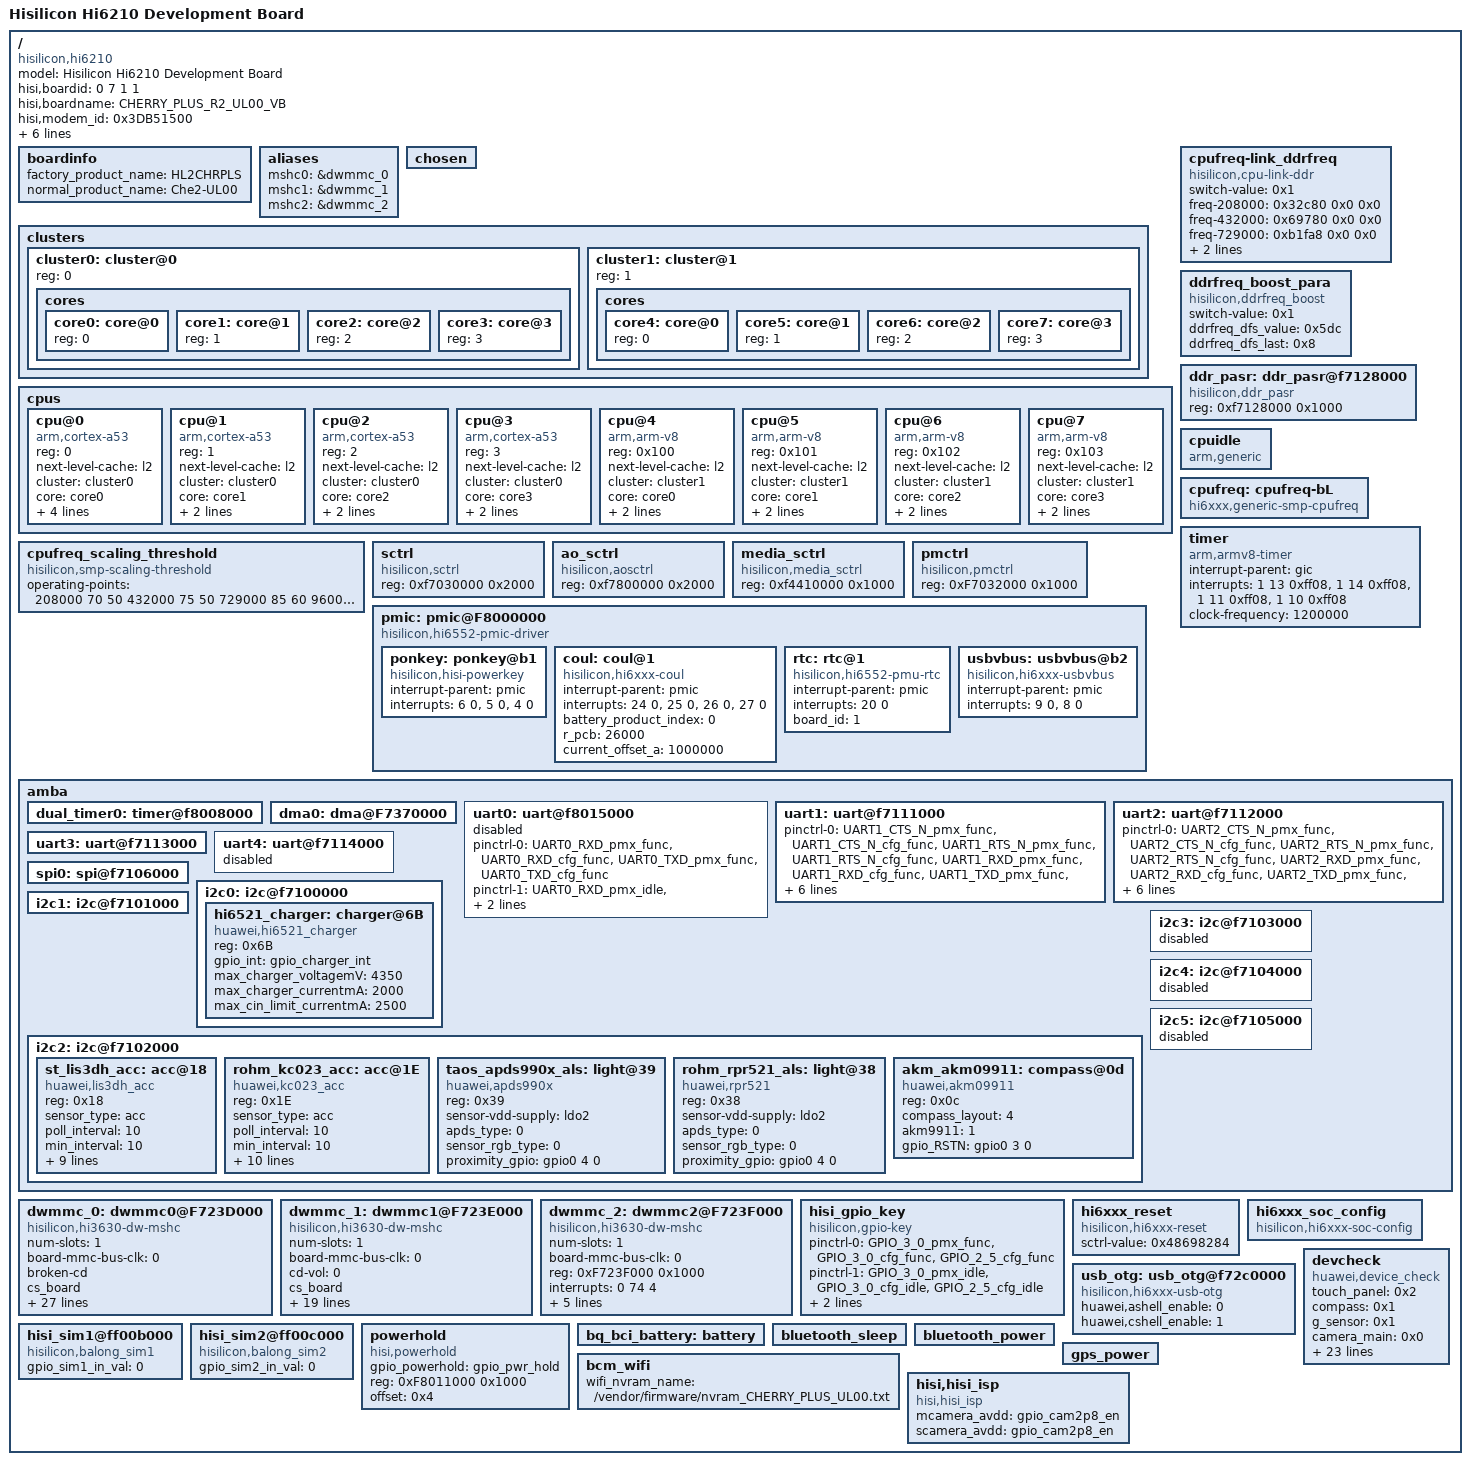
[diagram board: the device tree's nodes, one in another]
/*
 *  Copyright (C) 2014 Hisilicon Ltd.
 *  Author: Bintian Wang <bintian.wang@huawei.com>
 *
 *  This program is free software; you can redistribute it and/or modify
 *  it under the terms of the GNU General Public License version 2 as
 *  publishhed by the Free Software Foundation.
 */

/dts-v1/;
/memreserve/ 0x07000000 0x00400000;
/include/ "skeleton.dtsi"
/include/ "CHERRY_PLUS_R2_UL00_VB_pin.dtsi"
/include/ "./cherry_plus_r2/hi6220_gpio.dtsi"
/include/ "./cherry_plus_r2/hi6220_pinctrl.dtsi"
/include/ "CHERRY_PLUS_R2_UL00_VB_charger.dtsi"
/include/ "CHERRY_PLUS_R2_UL00_VB_pmic.dtsi"
/include/ "CHERRY_PLUS_R2_UL00_VB_gpio_logic.dtsi"
/include/ "./cherry_plus_r2/hi6220.dtsi"
/include/ "./cherry_plus_r2/hi6220_clk.dtsi"
/include/ "./cherry_plus_r2/hi6552_pmuclk.dtsi"
/include/ "./cherry_plus_r2/hi6xxx_ddr3.dtsi"
/include/ "./cherry_plus_r2/hi6552_pmic_mntn.dtsi"
/include/ "./cherry_plus_r2/hi6xxx_mtcmos.dtsi"
/include/ "./cherry_plus_r2/hi6220_memory.dtsi"
/include/ "./cherry_plus_r2/bq_bci_battery.dtsi"
/include/ "./cherry_plus_r2/hi6220_touchscreen.dtsi"
/include/ "./cherry_plus_r2/hi6220_vcodec.dtsi"
/include/ "./cherry_plus_r2/hi6220_camera.dtsi"
/include/ "./cherry_plus_r2/hi6220_videoconfig.dtsi"
/include/ "./cherry_plus_r2/hi6220_mali450.dtsi"
/include/ "./cherry_plus_r2/hi6220_fb.dtsi"
/include/ "./cherry_plus_r2/hi6220_mipi_tm_nt35521.dtsi"
/include/ "./cherry_plus_r2/hi6220_mipi_boe_nt35521.dtsi" 
/include/ "./cherry_plus_r2/hi6220_mipi_cmi_nt35521.dtsi" 
/include/ "./cherry_plus_r2/hi6220_mipi_yassy_hx8394.dtsi"
/include/ "./cherry_plus_r2/hi6220_mipi_tm_r61318.dtsi"
/include/ "./cherry_plus_r2/hi6220_mipi_cmi_otm1284a.dtsi"
/include/ "./cherry_plus_r2/hi6220_mipi_yassy_ili9881-3.dtsi"

/* /include/ "./cherry_plus_r2/hi6220_otm1282b.dtsi" */
/include/ "./cherry_plus_r2/hi6220_mipi_jdi_otm1902b.dtsi"
/include/ "./cherry_plus_r2/test_hi6xxx_regulator.dtsi"
/include/ "./cherry_plus_r2/hi6220_tsensor.dtsi"
/include/ "./cherry_plus_r2/hi6xxx_hkadc.dtsi"
/include/ "./cherry_plus_r2/hi6220_audio.dtsi"
/include/ "./cherry_plus_r2/hi6220_clk_stub.dtsi"
/include/ "./cherry_plus_r2/hi6220_hall.dtsi"

/include/ "./cherry_plus_r2/hisi_vibrator.dtsi"
/include/ "./cherry_plus_r2/huawei_wifi.dtsi"
/include/ "./cherry_plus_r2/huawei_bluetooth.dtsi"
/include/ "./cherry_plus_r2/huawei_gps.dtsi"
/include/ "./cherry_plus_r2/hisi_hi6xxx_noc.dtsi"
/include/ "./cherry_plus_r2/huawei_connectivity.dtsi"
/ {
	model = "Hisilicon Hi6210 Development Board";
	compatible = "hisilicon,hi6210";
	hisi,boardid = <0 7 1 1>;
	hisi,boardname = "CHERRY_PLUS_R2_UL00_VB";
	hisi,modem_id = <0x3DB51500>;
	hisi,product_name = "CHERRY_PLUS_UL00";
	mntn,acpu-scaddr = <0xf6504000 0x1000>;
	power,busdfs = <0x1>;
	power,localtimer = <0x0>;
	clk,support_odd_div = <0>;
	#address-cells = <1>;
	#size-cells = <1>;
	interrupt-parent = <&gic>;
	
	boardinfo{
	factory_product_name = "HL2CHRPLS";
	normal_product_name = "Che2-UL00";
	};
	aliases{
	    mshc0 = &dwmmc_0;
	    mshc1 = &dwmmc_1;
	    mshc2 = &dwmmc_2;
	};

	chosen {};

	clusters {
		#address-cells = <1>;
		#size-cells = <0>;

		cluster0: cluster@0 { /*A53 cluster*/
			reg = <0>;
			cores {
				#address-cells = <1>;
				#size-cells = <0>;

				core0: core@0 {
					reg = <0>;
				};

				core1: core@1 {
					reg = <1>;
				};

				core2: core@2 {
					reg = <2>;
				};

				core3: core@3 {
					reg = <3>;
				};

			};
		};

		cluster1: cluster@1 { /*A53 cluster*/
			reg = <1>;
			cores {
				#address-cells = <1>;
				#size-cells = <0>;

				core4: core@0 {
					reg = <0>;
				};

				core5: core@1 {
					reg = <1>;
				};

				core6: core@2 {
					reg = <2>;
				};

				core7: core@3 {
					reg = <3>;
				};
			};
		};
	};

	cpus {
		#address-cells = <1>;
		#size-cells = <0>;

		cpu@0 {
			compatible = "arm,cortex-a53";
			device_type = "cpu";
			reg = <0>;
			next-level-cache = <&l2>;			
			cluster = <&cluster0>;
			core = <&core0>;
			clock-frequency = <0>;
			clock-latency = <0>;
			operating-points = <
				/* kHz  uV */
				208000  0
				432000  0
				729000  0
				960000  0
				1200000 0
			>;
			
		};

		cpu@1 {
			compatible = "arm,cortex-a53";
			device_type = "cpu";
			reg = <1>;
			next-level-cache = <&l2>;
			cluster = <&cluster0>;
			core = <&core1>;
			clock-frequency = <0>;
			clock-latency = <0>;
		};

		cpu@2 {
			compatible = "arm,cortex-a53";
			device_type = "cpu";
			reg = <2>;
			next-level-cache = <&l2>;
			cluster = <&cluster0>;
			core = <&core2>;
			clock-frequency = <0>;
			clock-latency = <0>;
		};

		cpu@3 {
			compatible = "arm,cortex-a53";
			device_type = "cpu";
			reg = <3>;
			next-level-cache = <&l2>;
			cluster = <&cluster0>;
			core = <&core3>;
			clock-frequency = <0>;
			clock-latency = <0>;
		};
		cpu@4 {
			compatible = "arm,arm-v8";
			device_type = "cpu";
			reg = <0x100>;
			next-level-cache = <&l2>;
			cluster = <&cluster1>;
			core = <&core0>;
			clock-frequency = <0>;
			clock-latency = <0>;
		};
		cpu@5 {
			compatible = "arm,arm-v8";
			device_type = "cpu";
			reg = <0x101>;
			next-level-cache = <&l2>;
			cluster = <&cluster1>;
			core = <&core1>;
			clock-frequency = <0>;
			clock-latency = <0>;
		};
		cpu@6 {
			compatible = "arm,arm-v8";
			device_type = "cpu";
			reg = <0x102>;
			next-level-cache = <&l2>;
			cluster = <&cluster1>;
			core = <&core2>;
			clock-frequency = <0>;
			clock-latency = <0>;
		};
		cpu@7 {
			compatible = "arm,arm-v8";
			device_type = "cpu";
			reg = <0x103>;
			next-level-cache = <&l2>;
			cluster = <&cluster1>;
			core = <&core3>;
			clock-frequency = <0>;
			clock-latency = <0>;
		};
		
	};	
	cpufreq-link_ddrfreq {
	        compatible = "hisilicon,cpu-link-ddr";
			switch-value = <0x1>;
			freq-208000 = <0x32c80 0x0 0x0>;
			freq-432000 = <0x69780 0x0 0x0>;
			freq-729000 = <0xb1fa8 0x0 0x0>;
			freq-960000 = <0xea600 0x0 0x61a80>;
			freq-1200000 = <0x124f80 0x0 0x61a80>;
        };

    ddrfreq_boost_para {
            compatible = "hisilicon,ddrfreq_boost";
            switch-value = <0x1>; 
            ddrfreq_dfs_value = <0x5dc>;   
            ddrfreq_dfs_last = <0x8>; 
        };  
    /* ddr pasr */
    ddr_pasr: ddr_pasr@f7128000 {
        compatible = "hisilicon,ddr_pasr";
        reg = <0xf7128000 0x1000>;
        status = "ok";
    };  
	cpuidle {
	        compatible = "arm,generic";
	        status = "ok";
        };
	
	/* cpufreq  device */
	cpufreq: cpufreq-bL {
		compatible = "hi6xxx,generic-smp-cpufreq";
	};

        cpufreq_scaling_threshold {
                compatible = "hisilicon,smp-scaling-threshold";
                operating-points = <
                        /* kHz  up_threshold down_threshold*/
                        208000   70   50
                        432000   75   50
                        729000   85   60
                        960000   85   70
                        1200000  90   70
                >;
        };

	timer {
	    compatible = "arm,armv8-timer";
	    interrupt-parent = <&gic>;
	    interrupts = <1 13 0xff08>,
	                 <1 14 0xff08>,
	                 <1 11 0xff08>,
	                 <1 10 0xff08>;
	    clock-frequency = <1200000>;
	};

	sctrl: sctrl {
		compatible = "hisilicon,sctrl";
		reg = <0xf7030000 0x2000>;
		status = "ok";
	};

	ao_sctrl: ao_sctrl {
		compatible = "hisilicon,aosctrl";
		reg = <0xf7800000 0x2000>;
		status = "ok";
	};
	
	media_sctrl: media_sctrl {
		compatible = "hisilicon,media_sctrl";
		reg = <0xf4410000 0x1000>;
		status = "ok";
	};

	pmctrl: pmctrl {
		compatible = "hisilicon,pmctrl";
		reg = <0xF7032000 0x1000>;
		status = "ok";
	};
        pmic: pmic@F8000000 {
                compatible = "hisilicon,hi6552-pmic-driver";
                status = "ok";
                ponkey:ponkey@b1{
                        compatible = "hisilicon,hisi-powerkey";
                        interrupt-parent = <&pmic>;
                        interrupts = <6 0>, <5 0>, <4 0>;
                        interrupt-names = "down", "up", "hold 1s";
                };
                coul: coul@1 {
                        compatible = "hisilicon,hi6xxx-coul";
                        interrupt-parent = <&pmic>;
                        interrupts = <24 0>, <25 0>, <26 0>, <27 0>;
                        interrupt-names = "cl_int_i", "cl_out_i", "cl_in_i", "vbat_int_i";
						battery_product_index = <0>;
						r_pcb = <26000>;	
						current_offset_a = <1000000>;						
						status = "ok";
                };
			
                rtc: rtc@1 {
                        compatible = "hisilicon,hi6552-pmu-rtc";
                        interrupt-parent = <&pmic>;
                        interrupts = <20 0>;
                        interrupt-names = "hi6552_pmu_rtc";
						board_id = <1>;
                };
                usbvbus:usbvbus@b2{
			compatible = "hisilicon,hi6xxx-usbvbus";
			interrupt-parent = <&pmic>;
			interrupts = <9 0>, <8 0>;
			interrupt-names = "connect", "disconnect";
		};
	};

	amba {
		dual_timer0: timer@f8008000 {
			status = "ok";
		};

		dma0: dma@F7370000 {
			status = "ok";
		};

		uart0: uart@f8015000 {	/* console */
			pinctrl-names = "default", "idle";
			pinctrl-0 = <&UART0_RXD_pmx_func
			             &UART0_RXD_cfg_func
				     &UART0_TXD_pmx_func
				     &UART0_TXD_cfg_func>;
			pinctrl-1 = <&UART0_RXD_pmx_idle
			             &UART0_RXD_cfg_idle
				     &UART0_TXD_pmx_idle
			             &UART0_TXD_cfg_idle>;
			status = "disabled";
		};
		uart1: uart@f7111000 {
			pinctrl-names = "default", "idle";
			pinctrl-0 = <&UART1_CTS_N_pmx_func
			             &UART1_CTS_N_cfg_func
			             &UART1_RTS_N_pmx_func
				     &UART1_RTS_N_cfg_func
				     &UART1_RXD_pmx_func
				     &UART1_RXD_cfg_func
				     &UART1_TXD_pmx_func
				     &UART1_TXD_cfg_func>;
			pinctrl-1 = <&UART1_CTS_N_pmx_idle
			             &UART1_CTS_N_cfg_idle
			             &UART1_RTS_N_pmx_idle
				     &UART1_RTS_N_cfg_idle
				     &UART1_RXD_pmx_idle
				     &UART1_RXD_cfg_idle
				     &UART1_TXD_pmx_idle
				     &UART1_TXD_cfg_idle>;
			status = "ok";
		};
		uart2: uart@f7112000 {
			pinctrl-names = "default", "idle";
			pinctrl-0 = <&UART2_CTS_N_pmx_func
			             &UART2_CTS_N_cfg_func
			             &UART2_RTS_N_pmx_func
				     &UART2_RTS_N_cfg_func
				     &UART2_RXD_pmx_func
				     &UART2_RXD_cfg_func
				     &UART2_TXD_pmx_func
				     &UART2_TXD_cfg_func>;
			pinctrl-1 = <&UART2_CTS_N_pmx_idle
			             &UART2_CTS_N_cfg_idle
			             &UART2_RTS_N_pmx_idle
				     &UART2_RTS_N_cfg_idle
				     &UART2_RXD_pmx_idle
				     &UART2_RXD_cfg_idle
				     &UART2_TXD_pmx_idle
				     &UART2_TXD_cfg_idle>;
			status = "ok";
		};
		uart3: uart@f7113000 {
			status = "ok";
		};
		uart4: uart@f7114000 {
			status = "disabled";
		};

		spi0: spi@f7106000 {	
			status = "ok";
		};

		/*i2c bus node*/
		i2c0: i2c@f7100000 {
			status = "ok";
			hi6521_charger:charger@6B {
				compatible = "huawei,hi6521_charger";
				reg = <0x6B>;				
				gpio_int = <&gpio_charger_int>;
				max_charger_voltagemV = <4350>;
				max_charger_currentmA = <2000>;
				max_cin_limit_currentmA = <2500>;
				status = "ok";
			};

		};
		i2c1: i2c@f7101000 {
			status = "ok";			
		};
		i2c2: i2c@f7102000 {
			status = "ok";
			st_lis3dh_acc:acc@18{
				compatible="huawei,lis3dh_acc";
				reg = <0x18>;
				sensor_type="acc";
				poll_interval=<10>;
				min_interval=<10>;
				g_range=<0>;
				axis_map_x=<0>;
				axis_map_y=<1>;
				axis_map_z=<2>;
				negate_x=<1>;
				negate_y=<1>;
				negate_z=<0>;
				gpio_int1=<0>;
				gpio_int2=<0>;
				status = "ok";
			};
			rohm_kc023_acc:acc@1E{
				compatible="huawei,kc023_acc";
				reg = <0x1E>;
				sensor_type="acc";
				poll_interval=<10>;
				min_interval=<10>;
				g_range=<0>;
				accel_res=<3>;
				axis_map_x=<0>;
				axis_map_y=<1>;
				axis_map_z=<2>;
				negate_x=<1>;
				negate_y=<1>;
				negate_z=<0>;
				gpio_int1=<0>;
				gpio_int2=<0>;
				status = "ok";
			};
			taos_apds990x_als:light@39{
				compatible="huawei,apds990x";
				reg = <0x39>;
				sensor-vdd-supply = <&ldo2>;
				apds_type=<0>;
				sensor_rgb_type=<0>;
				proximity_gpio=<&gpio0 4 0>;
				status = "ok";
			};
			rohm_rpr521_als:light@38{
				compatible="huawei,rpr521";
				reg = <0x38>;
				sensor-vdd-supply = <&ldo2>;
				apds_type=<0>;
				sensor_rgb_type=<0>;
				proximity_gpio=<&gpio0 4 0>;
				status = "ok";
			};
			akm_akm09911:compass@0d{
				compatible="huawei,akm09911";
				reg = <0x0c>;
				compass_layout=<4>;
				akm9911=<1>;
				gpio_RSTN=<&gpio0 3 0>;
				status = "ok";
			};
		};
		i2c3: i2c@f7103000 {
			status = "disabled";
		};
		i2c4: i2c@f7104000 {
			status = "disabled";
		};
		i2c5: i2c@f7105000 {
			status = "disabled";
		};

	};
	
	/*watchpoint: watchpoint@F6580000 {
		compatible = "hisilicon,watchpoint";
		status = "ok";
	};*/
	/* emmc */
	dwmmc_0: dwmmc0@F723D000 {
 		compatible = "hisilicon,hi3630-dw-mshc";
		num-slots = <1>;
		board-mmc-bus-clk = <0>;
		broken-cd;
		cs_board;
        	caps2-mmc-hs200-1_8v;
 	        reg = <0xF723D000 0x1000>;
 		interrupts = <0 72 4>;
 		#address-cells = <1>;
 		#size-cells = <0>;
 		clocks = <&clk_mmc0_sample>, <&clk_mmc0>;
 		clock-names = "ciu", "biu";
		vmmc-supply = <&ldo19>;
		pinctrl-names = "default","idle";
		pinctrl-0 = <&EMMC_CLK_pmx_func
			         &EMMC_CLK_cfg_func
					 &EMMC_CMD_pmx_func
			         &EMMC_CMD_cfg_func
					 &EMMC_DATA0_pmx_func
					 &EMMC_DATA0_cfg_func
					 &EMMC_DATA1_pmx_func
					 &EMMC_DATA1_cfg_func
					 &EMMC_DATA2_pmx_func
					 &EMMC_DATA2_cfg_func
					 &EMMC_DATA3_pmx_func
					 &EMMC_DATA3_cfg_func
					 &EMMC_DATA4_pmx_func
					 &EMMC_DATA4_cfg_func
					 &EMMC_DATA5_pmx_func
					 &EMMC_DATA5_cfg_func
					 &EMMC_DATA6_pmx_func
					 &EMMC_DATA6_cfg_func
					 &EMMC_DATA7_pmx_func
					 &EMMC_DATA7_cfg_func>;
		pinctrl-1 = <&EMMC_CLK_pmx_idle
			         &EMMC_CLK_cfg_idle
					 &EMMC_CMD_pmx_idle
					 &EMMC_CMD_cfg_idle
					 &EMMC_DATA0_pmx_idle
					 &EMMC_DATA0_cfg_idle
					 &EMMC_DATA1_pmx_idle
					 &EMMC_DATA1_cfg_idle
					 &EMMC_DATA2_pmx_idle
					 &EMMC_DATA2_cfg_idle
					 &EMMC_DATA3_pmx_idle
					 &EMMC_DATA3_cfg_idle
					 &EMMC_DATA4_pmx_idle
					 &EMMC_DATA4_cfg_idle
					 &EMMC_DATA5_pmx_idle
					 &EMMC_DATA5_cfg_idle
					 &EMMC_DATA6_pmx_idle
					 &EMMC_DATA6_cfg_idle
					 &EMMC_DATA7_pmx_idle
					 &EMMC_DATA7_cfg_idle>;			 
     };
	 
	dwmmc_1: dwmmc1@F723E000 {
 		compatible = "hisilicon,hi3630-dw-mshc";
		num-slots = <1>;
		board-mmc-bus-clk = <0>;
		cd-vol = <0>;	
		cs_board;
		card-detect-delay = <200>;
		cd-gpio = <&gpio_sd_det>;
 	    reg = <0xF723E000 0x1000>;
 		interrupts = <0 73 4>;
 		#address-cells = <1>;
 		#size-cells = <0>;
 		clocks = <&clk_mmc1_sample>, <&clk_mmc1>;
 		clock-names = "ciu", "biu";
		vqmmc-supply = <&ldo7>;
		vmmc-supply = <&ldo10>;
		pinctrl-names = "default","idle";
		pinctrl-0 = <&SD_CLK_pmx_func
		             &SD_CLK_cfg_func
					 &SD_CMD_pmx_func
					 &SD_CMD_cfg_func
					 &SD_DATA0_pmx_func
					 &SD_DATA0_cfg_func
					 &SD_DATA1_pmx_func
					 &SD_DATA1_cfg_func
					 &SD_DATA2_pmx_func
					 &SD_DATA2_cfg_func
					 &SD_DATA3_pmx_func
					 &SD_DATA3_cfg_func>;
		pinctrl-1 = <&SD_CLK_pmx_idle
		             &SD_CLK_cfg_idle
					 &SD_CMD_pmx_idle
					 &SD_CMD_cfg_idle
					 &SD_DATA0_pmx_idle
					 &SD_DATA0_cfg_idle
					 &SD_DATA1_pmx_idle
					 &SD_DATA1_cfg_idle
					 &SD_DATA2_pmx_idle
					 &SD_DATA2_cfg_idle
					 &SD_DATA3_pmx_idle
					 &SD_DATA3_cfg_idle>;			 
     };

	/* sdio */
	dwmmc_2: dwmmc2@F723F000 {
 		compatible = "hisilicon,hi3630-dw-mshc";
		num-slots = <1>;
		board-mmc-bus-clk = <0>;
		reg = <0xF723F000 0x1000>;
 		interrupts = <0 74 4>;
 		#address-cells = <1>;
 		#size-cells = <0>;
 		clocks = <&clk_mmc2_sample>, <&clk_mmc2>;
 		clock-names = "ciu", "biu";
		keep-power-in-suspend;
		emmc-ldo-supply = <&ldo2>;
		/* emmc-lvs-supply = <&ldo1>; */
		pinctrl-names = "default","idle";
		pinctrl-0 = <>;
		pinctrl-1 = <>;			 
     };

	hisi_gpio_key {
	compatible = "hisilicon,gpio-key";
	pinctrl-names = "default", "idle";
	pinctrl-0 = <&GPIO_3_0_pmx_func
		     &GPIO_3_0_cfg_func
	             &GPIO_2_5_cfg_func>;
	pinctrl-1 = <&GPIO_3_0_pmx_idle
	             &GPIO_3_0_cfg_idle
		     &GPIO_2_5_cfg_idle>;
	gpio-keyup,gpio-irq = <&gpio_volume1_n>;
	gpio-keydown,gpio-irq = <&gpio_volume2_n>;
	status = "ok";
	};
		
	hi6xxx_reset:hi6xxx_reset {
		compatible = "hisilicon,hi6xxx-reset";
		sctrl-value = <0x48698284>;
	};

	hi6xxx_soc_config:hi6xxx_soc_config {
		compatible = "hisilicon,hi6xxx-soc-config";
	};

	usb_otg: usb_otg@f72c0000 {
		compatible = "hisilicon,hi6xxx-usb-otg";
		huawei,ashell_enable = <0>;
		huawei,cshell_enable = <1>;
	};

    hisi_sim1@ff00b000{
		compatible = "hisilicon,balong_sim1";
		gpio_sim1_in_val          = <0>;
	};
	
	hisi_sim2@ff00c000{
		compatible = "hisilicon,balong_sim2";
		gpio_sim2_in_val          = <0>;

	};
	
	powerhold:powerhold {
		compatible = "hisi,powerhold";
		gpio_powerhold = <&gpio_pwr_hold>; /*gpio0_0*/
		reg = <0xF8011000 0x1000>;  /*gpio0 base address*/
		offset = <0x4>;             /*gpio0  offset address*/
		status = "ok";
	};
	
	devcheck {
		compatible = "huawei,device_check";
		touch_panel = <0x2>;
		compass = <0x1>;
		g_sensor = <0x1>;
		camera_main = <0x0>;
		camera_slave = <0x0>;
		keypad = <0x0>;
		aps = <0x0>;
		gyroscope = <0x0>;
		nfc = <0x0>;
		dc_dc = <0x0>;
		speaker = <0x0>;
		ofn = <0x0>;
		tps = <0x0>;
		l_sensor = <0x2>;
		charge = <0x1>;
		battery = <0x0>;
		nct = <0x0>;
		mhl = <0x0>;
		audience = <0x0>;
		irda = <0x0>;
		hand_sensor = <0x0>;
		usb_switch = <0x0>;
		pmu_dcdc = <0x0>;
		fm = <0x0>;
		wifi = <0x1>;
		bt = <0x1>;
		gps = <0x1>;
		status = "ok";
	};

	/*fake_clk_ddrpll: fake_clk_ddrpll {
		compatible = "fixed-clock";
		#clock-cells = <0>;	
		clock-frequency = <800000000>;		
		clock-output-names = "fake_clk_ddrpll";
	};*/

	bq_bci_battery:battery {
		status = "ok";
	};
	bluetooth_sleep:bluetooth_sleep{
        status = "ok";
    };	
	bluetooth_power:bluetooth_power{
        status = "ok";
    };	
	gps_power:gps_power{
        status = "ok";
    };	
	bcm_wifi {
		wifi_nvram_name = "/vendor/firmware/nvram_CHERRY_PLUS_UL00.txt";
		status = "ok";
	};

	hisi,hisi_isp {
		compatible = "hisi,hisi_isp";
		mcamera_avdd = <&gpio_cam2p8_en>;
		scamera_avdd = <&gpio_cam2p8_en>;
	};

};
